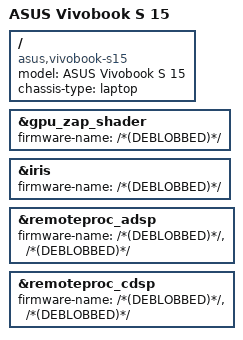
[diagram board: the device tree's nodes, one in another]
// SPDX-License-Identifier: BSD-3-Clause
/*
 * Copyright (c) 2023 Qualcomm Innovation Center, Inc. All rights reserved.
 * Copyright (c) 2024, Xilin Wu <wuxilin123@gmail.com>
 */

/dts-v1/;

#include "hamoa.dtsi"
#include "x1-asus-vivobook-s15.dtsi"

/ {
	model = "ASUS Vivobook S 15";
	compatible = "asus,vivobook-s15", "qcom,x1e80100";
	chassis-type = "laptop";
};

&gpu_zap_shader {
	firmware-name = "/*(DEBLOBBED)*/";
};

&iris {
	firmware-name = "/*(DEBLOBBED)*/";

	status = "okay";
};

&remoteproc_adsp {
	firmware-name = "/*(DEBLOBBED)*/",
			"/*(DEBLOBBED)*/";

	status = "okay";
};

&remoteproc_cdsp {
	firmware-name = "/*(DEBLOBBED)*/",
			"/*(DEBLOBBED)*/";

	status = "okay";
};

